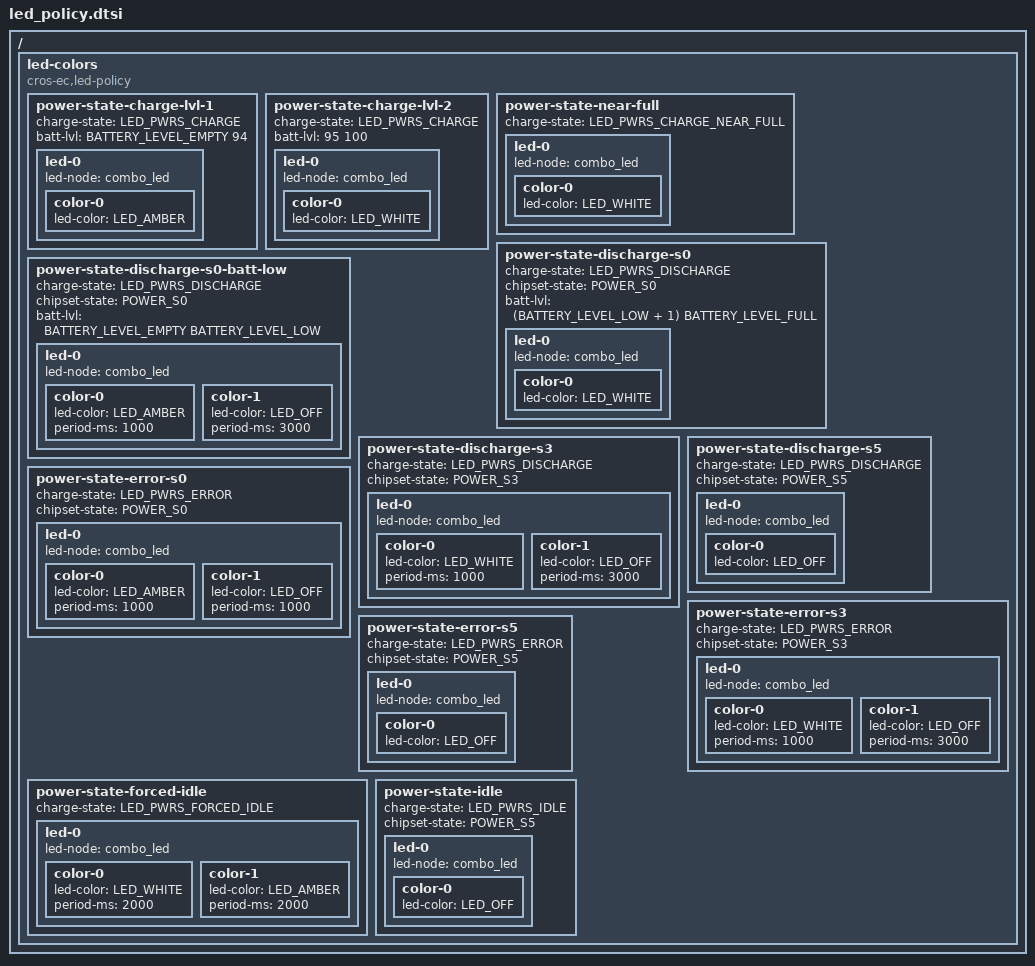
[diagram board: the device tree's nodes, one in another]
#include <dt-bindings/battery.h>

/ {
	led-colors {
		compatible = "cros-ec,led-policy";

		power-state-charge-lvl-1 {
			charge-state = "LED_PWRS_CHARGE";

			/* Battery display percent range (>= Empty, <= 94%) */
			batt-lvl = <BATTERY_LEVEL_EMPTY 94>;

			led-0 {
				led-node = <&combo_led>;

				color-0 {
					led-color = "LED_AMBER";
				};
			};
		};

		power-state-charge-lvl-2 {
			charge-state = "LED_PWRS_CHARGE";

			/* Battery display percent range (>= 95) */
			batt-lvl = <95 100>;

			led-0 {
				led-node = <&combo_led>;

				color-0 {
					led-color = "LED_WHITE";
				};
			};
		};

		power-state-near-full {
			charge-state = "LED_PWRS_CHARGE_NEAR_FULL";

			led-0 {
				led-node = <&combo_led>;

				color-0 {
					led-color = "LED_WHITE";
				};
			};
		};

		power-state-discharge-s0 {
			charge-state = "LED_PWRS_DISCHARGE";
			chipset-state = "POWER_S0";
			/* Battery display percent range (>= 11%, <= 100%) */
			batt-lvl = <(BATTERY_LEVEL_LOW + 1) BATTERY_LEVEL_FULL>;

			led-0 {
				led-node = <&combo_led>;

				color-0 {
					led-color = "LED_WHITE";
				};
			};
		};

		power-state-discharge-s0-batt-low {
			charge-state = "LED_PWRS_DISCHARGE";
			chipset-state = "POWER_S0";
			/* Battery display percent range (>= 0, <= 10%) */
			batt-lvl = <BATTERY_LEVEL_EMPTY BATTERY_LEVEL_LOW>;

			led-0 {
				led-node = <&combo_led>;

				/* Amber 1 sec on, 3 sec off */
				color-0 {
					led-color = "LED_AMBER";
					period-ms = <1000>;
				};
				color-1 {
					led-color = "LED_OFF";
					period-ms = <3000>;
				};
			};
		};

		power-state-discharge-s3 {
			charge-state = "LED_PWRS_DISCHARGE";
			chipset-state = "POWER_S3";

			led-0 {
				led-node = <&combo_led>;

				/* White 1 sec on, 3 sec off */
				color-0 {
					led-color = "LED_WHITE";
					period-ms = <1000>;
				};
				color-1 {
					led-color = "LED_OFF";
					period-ms = <3000>;
				};
			};
		};

		power-state-discharge-s5 {
			charge-state = "LED_PWRS_DISCHARGE";
			chipset-state = "POWER_S5";

			led-0 {
				led-node = <&combo_led>;

				color-0 {
					led-color = "LED_OFF";
				};
			};
		};

		power-state-error-s0 {
			charge-state = "LED_PWRS_ERROR";
			chipset-state = "POWER_S0";

			led-0 {
				led-node = <&combo_led>;

				/* Amber 1 sec on, 1 sec off */
				color-0 {
					led-color = "LED_AMBER";
					period-ms = <1000>;
				};
				color-1 {
					led-color = "LED_OFF";
					period-ms = <1000>;
				};
			};
		};

		power-state-error-s3 {
			charge-state = "LED_PWRS_ERROR";
			chipset-state = "POWER_S3";

			led-0 {
				led-node = <&combo_led>;

				/* White 1 sec on, 3 sec off */
				color-0 {
					led-color = "LED_WHITE";
					period-ms = <1000>;
				};
				color-1 {
					led-color = "LED_OFF";
					period-ms = <3000>;
				};
			};
		};

		power-state-error-s5 {
			charge-state = "LED_PWRS_ERROR";
			chipset-state = "POWER_S5";

			led-0 {
				led-node = <&combo_led>;

				color-0 {
					led-color = "LED_OFF";
				};
			};
		};

		power-state-forced-idle {
			charge-state = "LED_PWRS_FORCED_IDLE";

			led-0 {
				led-node = <&combo_led>;

				/* White 2 sec on, Amber 2 sec on */
				color-0 {
					led-color = "LED_WHITE";
					period-ms = <2000>;
				};
				color-1 {
					led-color = "LED_AMBER";
					period-ms = <2000>;
				};
			};
		};

		power-state-idle {
			charge-state = "LED_PWRS_IDLE";
			chipset-state = "POWER_S5";

			led-0 {
				led-node = <&combo_led>;

				/* LED off when S5, others do not change */
				color-0 {
					led-color = "LED_OFF";
				};
			};
		};
	};
};
